# AT32UC3C0128C device description
Architecture: AVR32_UC3; Family: AVR UC3
Registers are 32-bit, read-write, reset 0x0 unless marked. A register's access mark holds for its fields unless they carry their own. Offsets are from the block's base; [hi:lo] are bit positions; {n}, {i} and the like mark numbered series; 'fields as' and 'values as' point back to an identical list.

## INTC — Interrupt Controller
Instances: INTC 0xFFFF0000
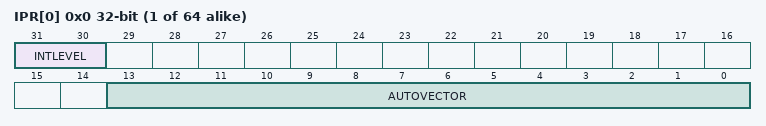
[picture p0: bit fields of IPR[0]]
{0x0+4i} IPR[{i}] (i=0..63) — Interrupt Priority Register
  [31:30] INTLEVEL — Interrupt Level
    {v}=INT{v} (v=0..3)
  [13:0] AUTOVECTOR — Handler offset
{0x100+4i} IRR[{i}] (i=0..63) ro — Interrupt Request Register
{0x200+4i} ICR[{i}] (i=0..3) ro — Interrupt Cause Register
  [5:0] CAUSE — Cause Group Number

## ACIFA — Analog Comparators Interface
Instances: ACIFA0 0xffff6000, ACIFA1 0xffff6400
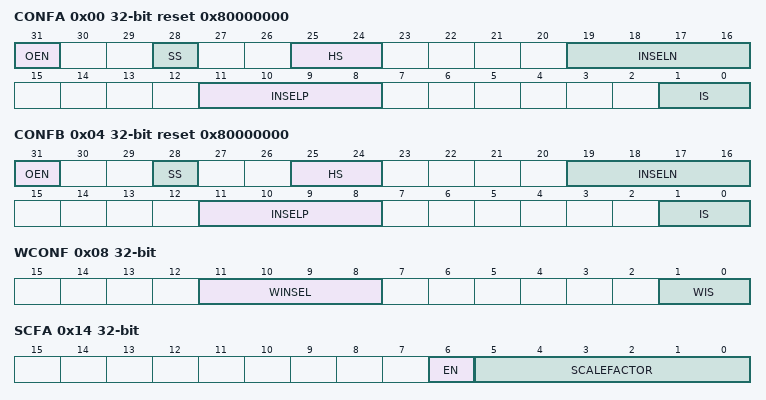
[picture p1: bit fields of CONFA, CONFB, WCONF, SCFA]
0x00 CONFA reset 0x80000000
  [31] OEN — OEN bit(s)
  [28] SS — SS bit(s)
  [25:24] HS — HS bit(s)
  [19:16] INSELN — INSELN bit(s)
  [11:8] INSELP — INSELP bit(s)
  [1:0] IS — IS bit(s)
0x04 CONFB reset 0x80000000
  fields as CONFA
0x08 WCONF
  [11:8] WINSEL — WINSEL bit(s)
  [1:0] WIS — WIS bit(s)
0x0C EVSRC0
  [3:0] EVSRC — EVSRC bit(s)
0x10 EVSRC1
  [3:0] EVSRC — EVSRC bit(s)
0x14 SCFA
  [6] EN — EN bit(s)
  [5:0] SCALEFACTOR — SCALEFACTOR bit(s)
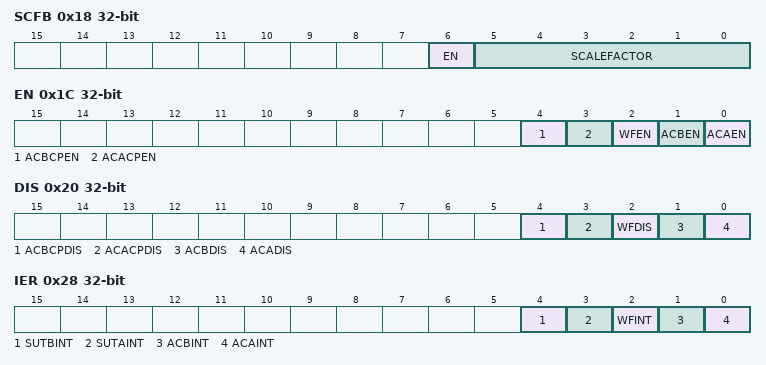
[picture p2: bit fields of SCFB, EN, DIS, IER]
0x18 SCFB
  [6] EN — EN bit(s)
  [5:0] SCALEFACTOR — SCALEFACTOR bit(s)
0x1C EN wo
  [4] ACBCPEN — ACBCPEN bit(s)
  [3] ACACPEN — ACACPEN bit(s)
  [2] WFEN — WFEN bit(s)
  [1] ACBEN — ACBEN bit(s)
  [0] ACAEN — ACAEN bit(s)
0x20 DIS
  [4] ACBCPDIS — ACBCPDIS bit(s)
  [3] ACACPDIS — ACACPDIS bit(s)
  [2] WFDIS — WFDIS bit(s)
  [1] ACBDIS — ACBDIS bit(s)
  [0] ACADIS — ACADIS bit(s)
0x24 SUT
  [15:0] SUT — SUT bit(s)
0x28 IER wo
  [4] SUTBINT — SUTBINT bit(s)
  [3] SUTAINT — SUTAINT bit(s)
  [2] WFINT — WFINT bit(s)
  [1] ACBINT — ACBINT bit(s)
  [0] ACAINT — ACAINT bit(s)
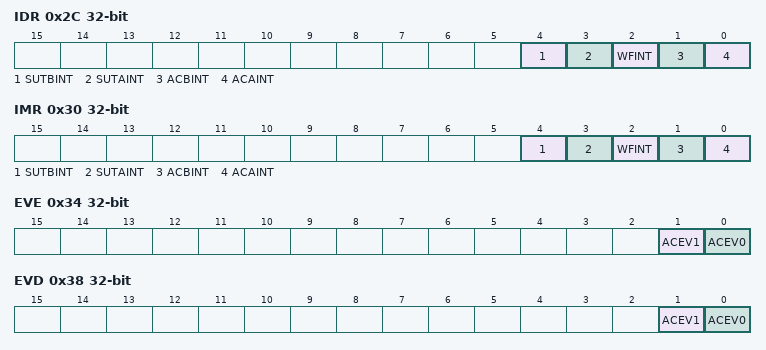
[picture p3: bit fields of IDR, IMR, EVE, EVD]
0x2C IDR wo
  fields as IER
0x30 IMR ro
  fields as IER
0x34 EVE wo
  [1] ACEV1 — ACEV1 bit(s)
  [0] ACEV0 — ACEV0 bit(s)
0x38 EVD wo
  [1] ACEV1 — ACEV1 bit(s)
  [0] ACEV0 — ACEV0 bit(s)
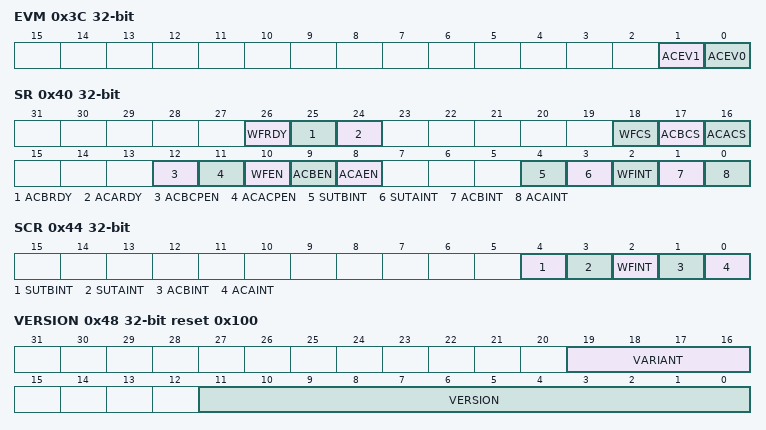
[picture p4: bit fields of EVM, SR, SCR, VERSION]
0x3C EVM ro
  [1] ACEV1 — ACEV1 bit(s)
  [0] ACEV0 — ACEV0 bit(s)
0x40 SR ro
  [26] WFRDY — WFRDY bit(s)
  [25] ACBRDY — ACBRDY bit(s)
  [24] ACARDY — ACARDY bit(s)
  [18] WFCS — WFCS bit(s)
  [17] ACBCS — ACBCS bit(s)
  [16] ACACS — ACACS bit(s)
  [12] ACBCPEN — ACBCPEN bit(s)
  [11] ACACPEN — ACACPEN bit(s)
  [10] WFEN — WFEN bit(s)
  [9] ACBEN — ACBEN bit(s)
  [8] ACAEN — ACAEN bit(s)
  [4] SUTBINT — SUTBINT bit(s)
  [3] SUTAINT — SUTAINT bit(s)
  [2] WFINT — WFINT bit(s)
  [1] ACBINT — ACBINT bit(s)
  [0] ACAINT — ACAINT bit(s)
0x44 SCR wo
  fields as IER
0x48 VERSION ro reset 0x100
  [19:16] VARIANT — VARIANT bit(s)
  [11:0] VERSION — VERSION bit(s)
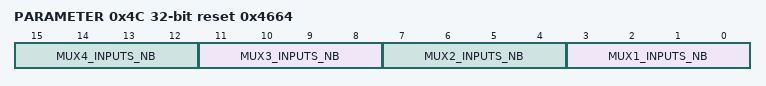
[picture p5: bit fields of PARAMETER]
0x4C PARAMETER ro reset 0x4664
  [4n-1:4n-4] MUX{n}_INPUTS_NB (n=1..4) — MUX{n}_INPUTS_NB bit(s)

## AST — Asynchronous Timer
Instances: AST 0xffff0c00
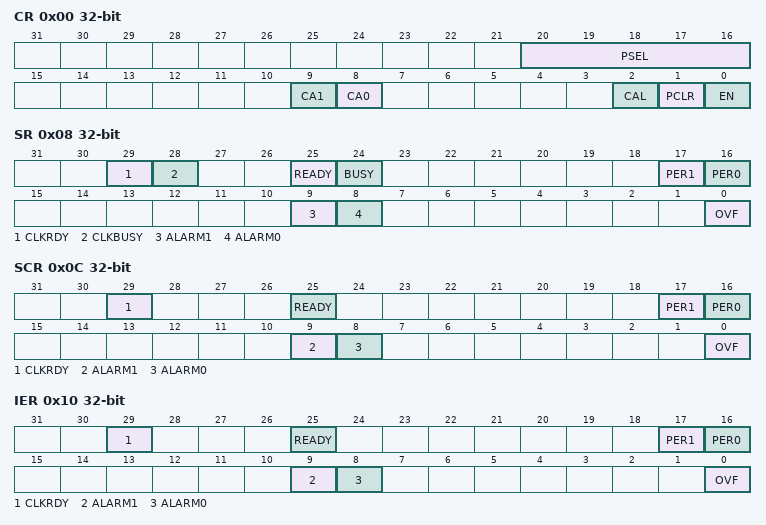
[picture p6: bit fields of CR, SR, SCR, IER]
0x00 CR — Control Register
  [20:16] PSEL — Prescale Select
  [9] CA1 — Clear on Alarm
  [8] CA0 — Clear on Alarm
  [2] CAL — Calendar mode
  [1] PCLR — Prescaler Clear (strobe)
  [0] EN — Enable
0x04 CV — Counter Value
  [30:0] VAL — AST Value
0x08 SR ro — Status Register
  [29] CLKRDY — Clock ready
  [28] CLKBUSY — Clock busy
  [25] READY — AST ready
  [24] BUSY — AST busy
  [17] PER1 — Periodic event 1
  [16] PER0 — Periodic event 0
  [9] ALARM1 — Alarm event 1
  [8] ALARM0 — Alarm event 0
  [0] OVF — Overflow
0x0C SCR wo — Status Clear Register
  [29] CLKRDY, [25] READY, [17] PER1, [16] PER0, [9] ALARM1, [8] ALARM0, [0] OVF
0x10 IER wo — Interrupt Enable Register
  [29] CLKRDY — Clock ready
  [25] READY — AST ready
  [17] PER1 — Periodic event 1
  [16] PER0 — Periodic event 0
  [9] ALARM1 — Alarm event 1
  [8] ALARM0 — Alarm event 0
  [0] OVF — Overflow
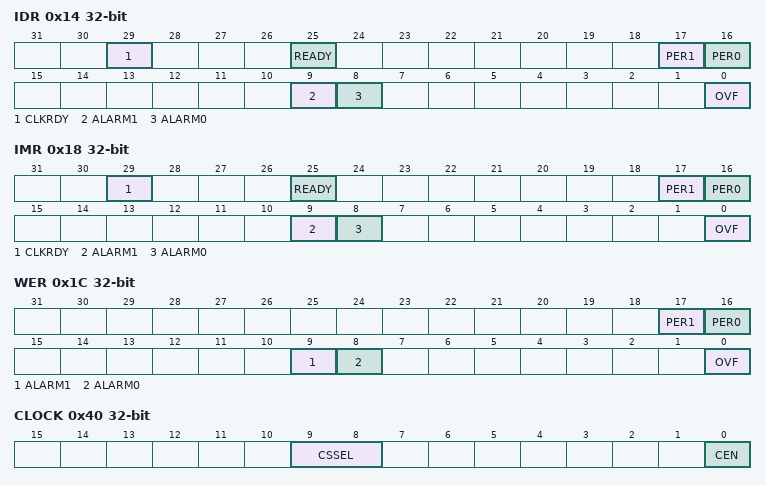
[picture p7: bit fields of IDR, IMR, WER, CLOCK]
0x14 IDR wo — Interrupt Disable Register
  fields as IER
0x18 IMR ro — Interrupt Mask Register
  fields as IER
0x1C WER — Wake Enable Register
  [17] PER1
  [16] PER0
  [9] ALARM1
  [8] ALARM0 — Alarm event 0
  [0] OVF
0x20 AR0 — Alarm Register 0
  [31:0] VALUE — Alarm Value
0x24 AR1 — Alarm Register 1
  [31:0] VALUE — Alarm Value
0x30 PIR0 — Periodic Interval Register 0
  [4:0] INSEL — Interval Select
0x34 PIR1 — Periodic Interval Register 1
  [4:0] INSEL — Interval Select
0x40 CLOCK — Clock Control Register
  [9:8] CSSEL — Clock Source Selection
  [0] CEN — Clock Enable
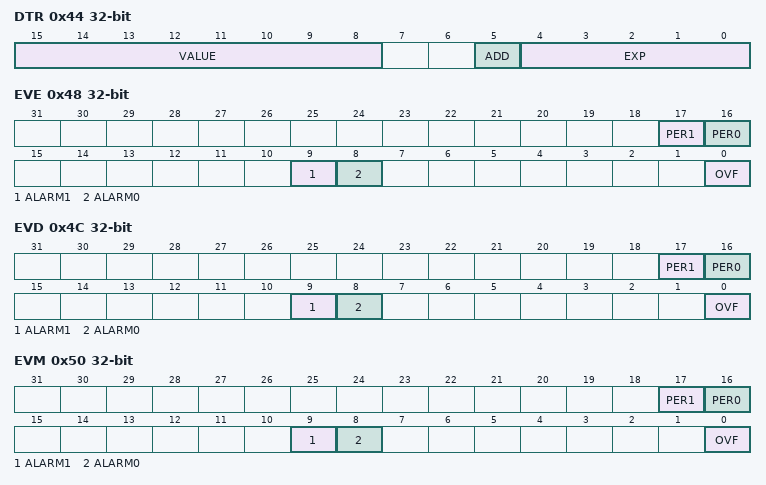
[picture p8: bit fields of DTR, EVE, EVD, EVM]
0x44 DTR — Digital Tuner Register
  [15:8] VALUE, [5] ADD, [4:0] EXP
0x48 EVE wo — Event Enable Register
  [17] PER1 — Periodic event 1
  [16] PER0 — Perioidc event 0
  [9] ALARM1 — Alarm event 1
  [8] ALARM0 — Alarm event 0
  [0] OVF — Overflow
0x4C EVD wo — Event Disable Register
  fields as EVE
0x50 EVM ro — Event Mask Register
  fields as EVE
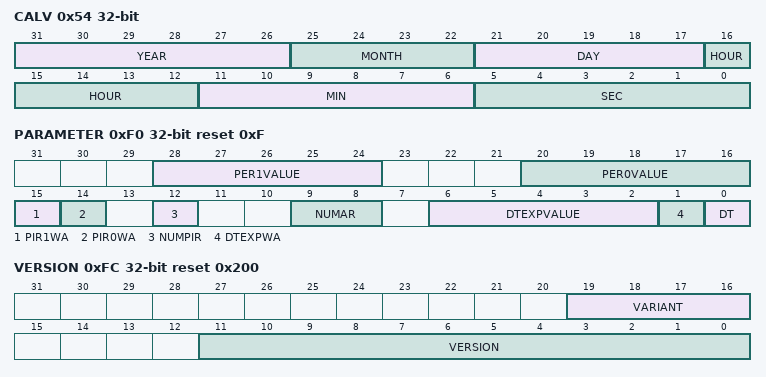
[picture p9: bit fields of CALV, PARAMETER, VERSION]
0x54 CALV — Calendar Value
  [31:26] YEAR
  [25:22] MONTH
  [21:17] DAY
  [16:12] HOUR
  [11:6] MIN — Minute
  [5:0] SEC — Second
0xF0 PARAMETER ro reset 0xF
  [28:24] PER1VALUE — Periodic Interval 1 Value
  [20:16] PER0VALUE — Periodic Interval 0 Value
  [15] PIR1WA — Perioidic Interval 1 Value
  [14] PIR0WA — Perioidc Interval 0 Writeable
  [12] NUMPIR — Number of periodic alarms
    0=ONE; 1=TWO
  [9:8] NUMAR — Number of alarm timers
    0=ZERO; 1=ONE; 2=TWO
  [6:2] DTEXPVALUE — Digital Tuner Exponent Value
  [1] DTEXPWA — Digital Tuner Exponent Writeable
  [0] DT — Digital Tuner
    0=OFF; 1=ON
0xFC VERSION ro reset 0x200
  [19:16] VARIANT, [11:0] VERSION
